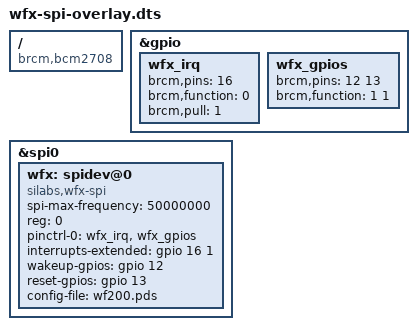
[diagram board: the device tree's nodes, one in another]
// overlay for SILABS WF200/WFM200/WF250 SPI
/dts-v1/;
/plugin/;

/*
 * In order to allow compilation out of kernel tree, avoid including headers
 * nor define macros in this overlay.
 *
 * Reminder about usefull defines:
 *   - from <dt-bindings/interrupt-controller/irq.h>
 *       #define IRQ_TYPE_EDGE_RISING    1
 *   - from <dt-bindings/gpio/gpio.h>
 *       #define GPIO_ACTIVE_LOW         0
 *       #define GPIO_ACTIVE_HIGH        1
 */

/ {
	compatible = "brcm,bcm2708";

	fragment@0 {
		target = <&gpio>;
		__overlay__ {
			wfx_irq: wfx_irq {
				brcm,pins = <16>;
				brcm,function = <0>; /* in */
				brcm,pull = <1>; /* pull-down */
			};
			wfx_gpios: wfx_gpios {
				brcm,pins = <12 13>;
				brcm,function = <1 1>; /* out */
			};
		};
	};

	fragment@1 {
		target = <&spi0>;
		__overlay__ {
			#address-cells = <1>; /* needed to avoid dtc warning */
			#size-cells = <0>; /* needed to avoid dtc warning */
			status = "okay";

			wfx: spidev@0 {
				spi-max-frequency = <50000000>; // necessary for dtparam
				reg = <0>;
				// "silabs,wfx-spi" is mandatory.
				// Use "siliconlabs,wfx-wlan-spi" for compatibility with driver < 1.3
				// Append "spidev" to be able to also use spidev driver
				compatible = "silabs,wfx-spi", "siliconlabs,wfx-wlan-spi";
				pinctrl-names = "default";
				pinctrl-0 = <&wfx_irq &wfx_gpios>;
				interrupts-extended = <&gpio 16 1>;
				wakeup-gpios = <&gpio 12 0>;
				reset-gpios = <&gpio 13 0>;
				config-file = "wf200.pds"; // necessary for dtparam
				status = "okay";
			};
		};
	};

	__overrides__ {
		config_file = <&wfx>,"config-file";
		spi_max_frequency = <&wfx>,"spi-max-frequency:0";
	};
};
